# MDR1986VK01 register map
File version: 1.0.2
Registers are 32-bit, read-write, no defined reset value unless marked. A register's access mark holds for its fields unless they carry their own. Offsets are from the block's base; [hi:lo] are bit positions; {n}, {i} and the like mark numbered series.

## MDR_PORTA — MDR_PORTA description
Base 0x40080000
Same registers: MDR_PORTB 0x40081000, MDR_PORTC 0x40082000, MDR_PORTD 0x40083000
0x00 KEY — KEY description
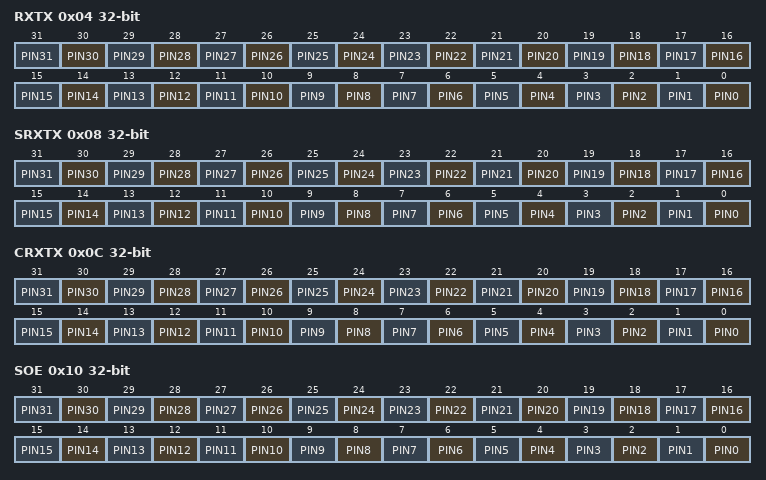
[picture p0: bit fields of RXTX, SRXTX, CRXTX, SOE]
0x04 RXTX — RXTX description
  [n] PIN{n} (n=0..31) — PIN{n} description
0x08 SRXTX — SRXTX description
  [n] PIN{n} (n=0..31) — PIN{n} description
0x0C CRXTX — CRXTX description
  [n] PIN{n} (n=0..31) — PIN{n} description
0x10 SOE — SOE description
  [n] PIN{n} (n=0..31) — PIN{n} description
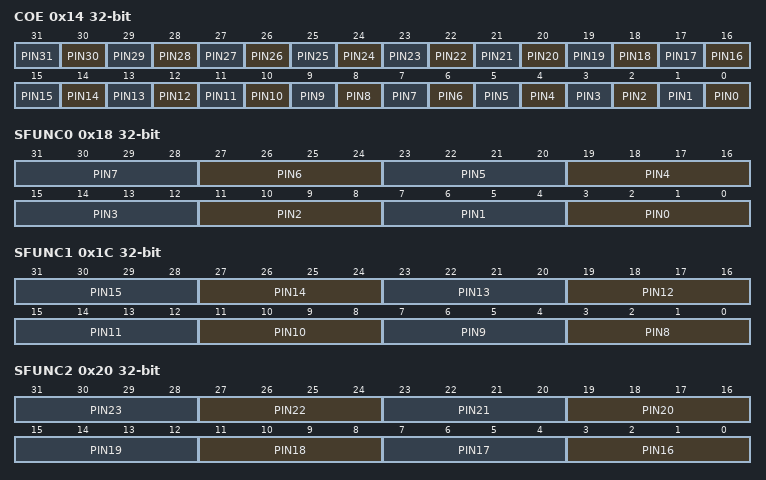
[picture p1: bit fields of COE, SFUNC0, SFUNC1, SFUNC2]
0x14 COE — COE description
  [n] PIN{n} (n=0..31) — PIN{n} description
0x18 SFUNC0 — SFUNC0 description
  [4n+3:4n] PIN{n} (n=0..7) — PIN{n} description
0x1C SFUNC1 — SFUNC1 description
  [4n-29:4n-32] PIN{n} (n=8..15) — PIN{n} description
0x20 SFUNC2 — SFUNC2 description
  [4n-61:4n-64] PIN{n} (n=16..23) — PIN{n} description
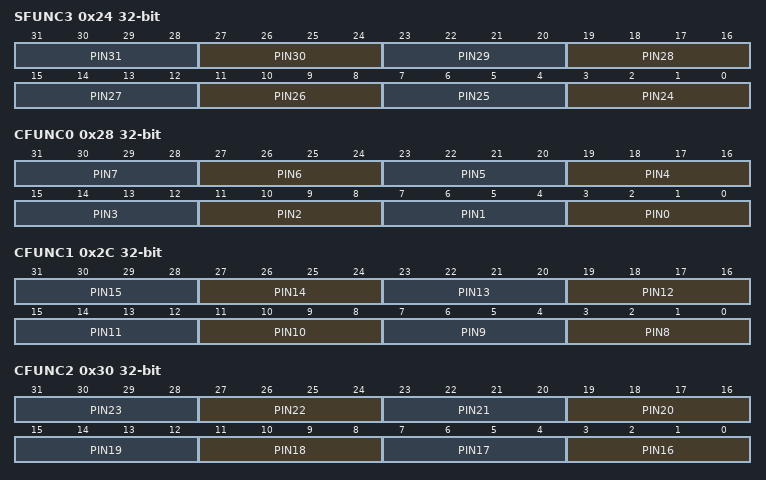
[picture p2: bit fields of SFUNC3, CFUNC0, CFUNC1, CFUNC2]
0x24 SFUNC3 — SFUNC3 description
  [4n-93:4n-96] PIN{n} (n=24..31) — PIN{n} description
0x28 CFUNC0 — CFUNC0 description
  [4n+3:4n] PIN{n} (n=0..7) — PIN{n} description
0x2C CFUNC1 — CFUNC1 description
  [4n-29:4n-32] PIN{n} (n=8..15) — PIN{n} description
0x30 CFUNC2 — CFUNC2 description
  [4n-61:4n-64] PIN{n} (n=16..23) — PIN{n} description
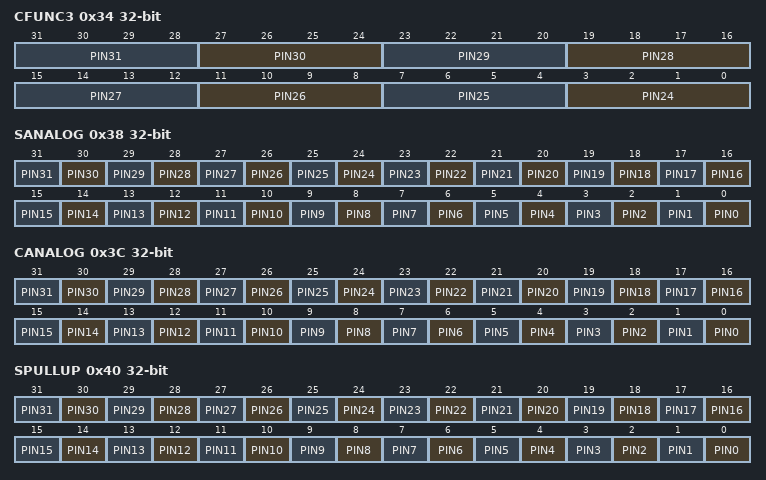
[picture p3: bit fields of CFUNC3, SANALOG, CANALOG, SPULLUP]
0x34 CFUNC3 — CFUNC3 description
  [4n-93:4n-96] PIN{n} (n=24..31) — PIN{n} description
0x38 SANALOG — SANALOG description
  [n] PIN{n} (n=0..31) — PIN{n} description
0x3C CANALOG — CANALOG description
  [n] PIN{n} (n=0..31) — PIN{n} description
0x40 SPULLUP — SPULLUP description
  [n] PIN{n} (n=0..31) — PIN{n} description
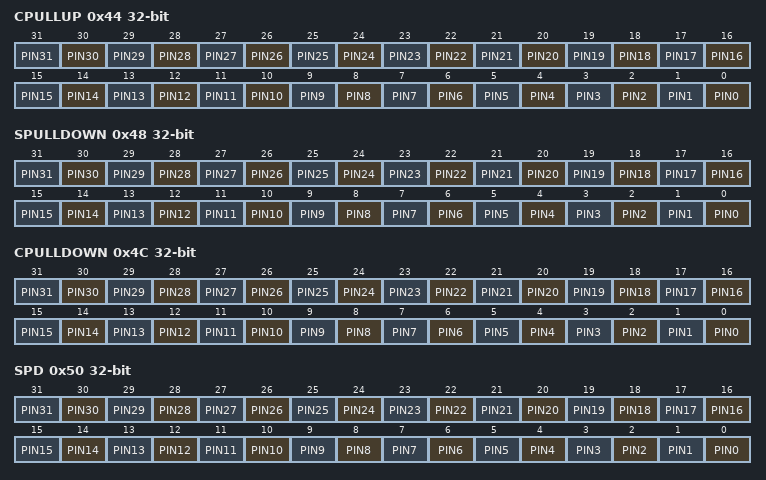
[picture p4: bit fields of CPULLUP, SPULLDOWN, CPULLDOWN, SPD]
0x44 CPULLUP — CPULLUP description
  [n] PIN{n} (n=0..31) — PIN{n} description
0x48 SPULLDOWN — SPULLDOWN description
  [n] PIN{n} (n=0..31) — PIN{n} description
0x4C CPULLDOWN — CPULLDOWN description
  [n] PIN{n} (n=0..31) — PIN{n} description
0x50 SPD — SPD description
  [n] PIN{n} (n=0..31) — PIN{n} description
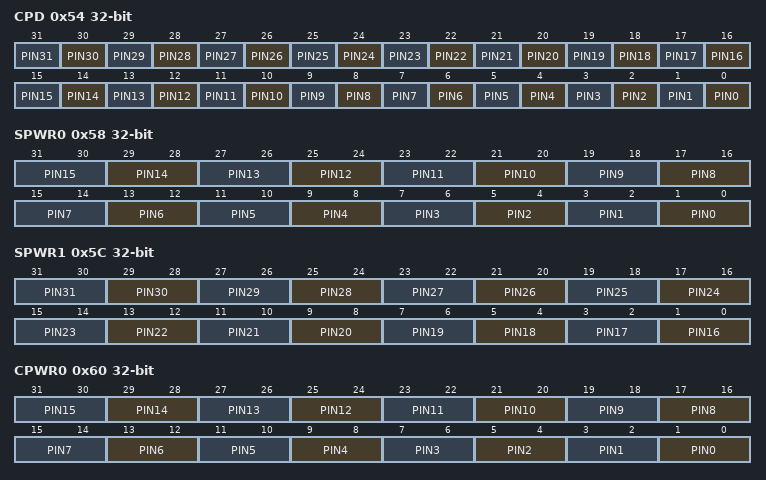
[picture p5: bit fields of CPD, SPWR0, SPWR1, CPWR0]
0x54 CPD — CPD description
  [n] PIN{n} (n=0..31) — PIN{n} description
0x58 SPWR0 — SPWR0 description
  [2n+1:2n] PIN{n} (n=0..15) — PIN{n} description
0x5C SPWR1 — SPWR1 description
  [2n-31:2n-32] PIN{n} (n=16..31) — PIN{n} description
0x60 CPWR0 — CPWR0 description
  [2n+1:2n] PIN{n} (n=0..15) — PIN{n} description
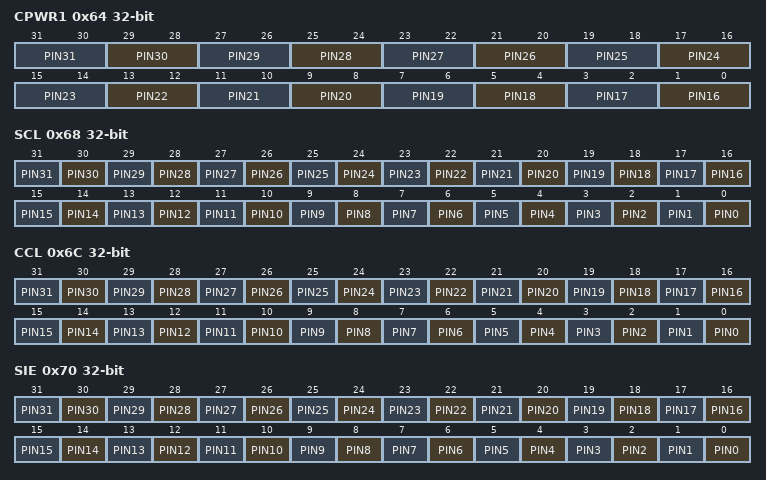
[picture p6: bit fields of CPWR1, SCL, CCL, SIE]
0x64 CPWR1 — CPWR1 description
  [2n-31:2n-32] PIN{n} (n=16..31) — PIN{n} description
0x68 SCL — SCL description
  [n] PIN{n} (n=0..31) — PIN{n} description
0x6C CCL — CCL description
  [n] PIN{n} (n=0..31) — PIN{n} description
0x70 SIE — SIE description
  [n] PIN{n} (n=0..31) — PIN{n} description
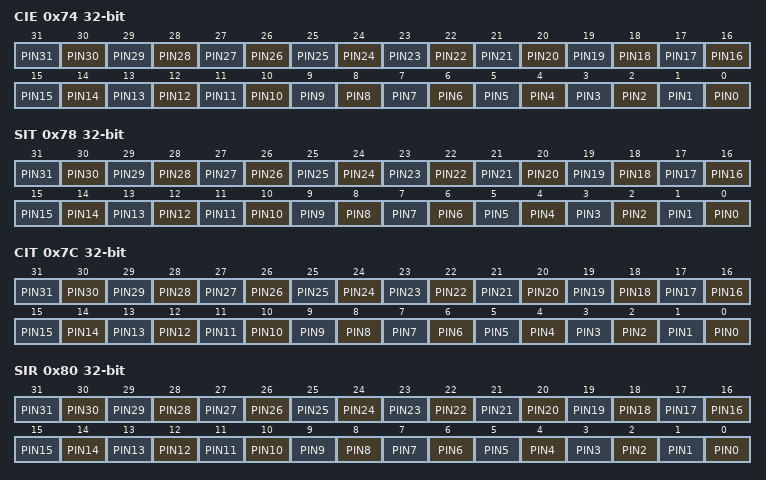
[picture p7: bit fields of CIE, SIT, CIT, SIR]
0x74 CIE — CIE description
  [n] PIN{n} (n=0..31) — PIN{n} description
0x78 SIT — SIT description
  [n] PIN{n} (n=0..31) — PIN{n} description
0x7C CIT — CIT description
  [n] PIN{n} (n=0..31) — PIN{n} description
0x80 SIR — SIR description
  [n] PIN{n} (n=0..31) — PIN{n} description
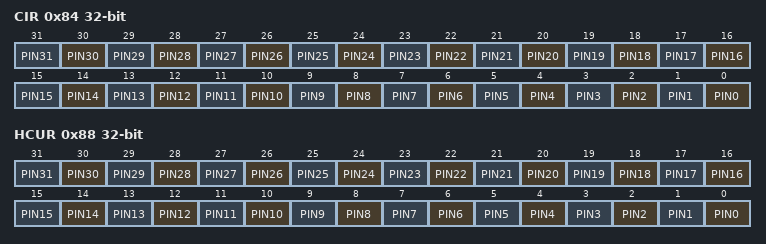
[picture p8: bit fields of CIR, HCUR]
0x84 CIR — CIR description
  [n] PIN{n} (n=0..31) — PIN{n} description
0x88 HCUR — HCUR description
  [n] PIN{n} (n=0..31) — PIN{n} description

## MDR_SSP0 — MDR_SSP0 description
Base 0x40089000
Same registers: MDR_SSP1 0x4008A000
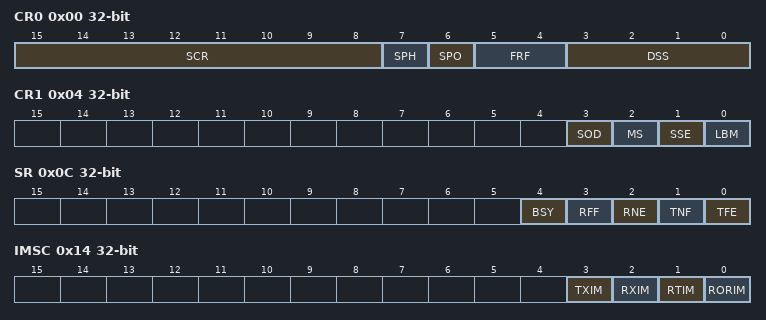
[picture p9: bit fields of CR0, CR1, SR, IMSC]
0x00 CR0 — CR0 description
  [15:8] SCR — SCR description
  [7] SPH — SPH description
  [6] SPO — SPO description
  [5:4] FRF — FRF description
  [3:0] DSS — DSS description
0x04 CR1 — CR1 description
  [3] SOD — SOD description
  [2] MS — MS description
  [1] SSE — SSE description
  [0] LBM — LBM description
0x08 DR — DR description
  [15:0] DATA — DATA description
0x0C SR — SR description
  [4] BSY — BSY description
  [3] RFF — RFF description
  [2] RNE — RNE description
  [1] TNF — TNF description
  [0] TFE — TFE description
0x10 CPSR — CPSR description
  [7:0] DVSR — DVSR description
0x14 IMSC — IMSC description
  [3] TXIM — TXIM description
  [2] RXIM — RXIM description
  [1] RTIM — RTIM description
  [0] RORIM — RORIM description
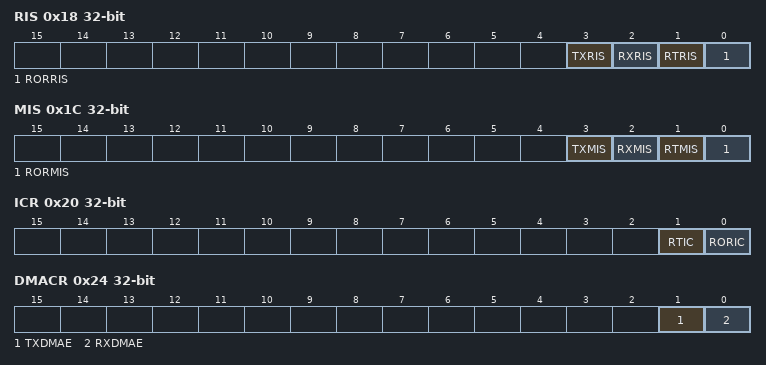
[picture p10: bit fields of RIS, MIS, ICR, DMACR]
0x18 RIS — RIS description
  [3] TXRIS — TXRIS description
  [2] RXRIS — RXRIS description
  [1] RTRIS — RTRIS description
  [0] RORRIS — RORRIS description
0x1C MIS — MIS description
  [3] TXMIS — TXMIS description
  [2] RXMIS — RXMIS description
  [1] RTMIS — RTMIS description
  [0] RORMIS — RORMIS description
0x20 ICR — ICR description
  [1] RTIC — RTIC description
  [0] RORIC — RORIC description
0x24 DMACR — DMACR description
  [1] TXDMAE — TXDMAE description
  [0] RXDMAE — RXDMAE description
